VERSION ""

NS_ :

BS_:

BU_: ECU_A ECU_B

BO_ 100 EngineStatus: 4 ECU_A
 SG_ EngineSpeed : 0|16@1+ (0.25,0) [0|16383.75] "rpm" Vector__XXX
 SG_ EngineTemp : 16|8@1+ (1,-40) [-40|215] "degC" Vector__XXX

BO_ 200 MuxMessage: 4 ECU_A
 SG_ Selector M : 0|4@1+ (1,0) [0|15] "" Vector__XXX
 SG_ CommonSig : 4|8@1+ (1,0) [0|255] "" Vector__XXX
 SG_ BranchA m1 : 16|8@1+ (2,0) [0|510] "" Vector__XXX
 SG_ BranchB m2 : 24|8@1+ (1,0) [0|255] "" Vector__XXX

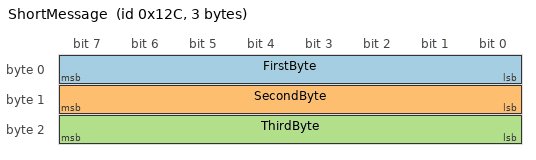
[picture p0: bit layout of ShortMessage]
BO_ 300 ShortMessage: 3 ECU_A
 SG_ FirstByte : 0|8@1+ (1,0) [0|255] "" Vector__XXX
 SG_ SecondByte : 8|8@1+ (1,0) [0|255] "" Vector__XXX
 SG_ ThirdByte : 16|8@1+ (1,0) [0|255] "" Vector__XXX

BO_ 400 EventMessage: 2 ECU_B
 SG_ EventCounter : 0|8@1+ (1,0) [0|255] "" Vector__XXX
 SG_ EventState : 8|4@1+ (1,0) [0|15] "" Vector__XXX

BA_DEF_ BO_  "GenMsgCycleTime" INT 0 1000000;
BA_DEF_DEF_  "GenMsgCycleTime" 0;
BA_ "GenMsgCycleTime" BO_ 100 100;
BA_ "GenMsgCycleTime" BO_ 200 200;
BA_ "GenMsgCycleTime" BO_ 300 500;

VAL_ 200 Selector 1 "BranchA" 2 "BranchB" ;
VAL_ 400 EventState 0 "Idle" 1 "Active" 15 "Error" ;
